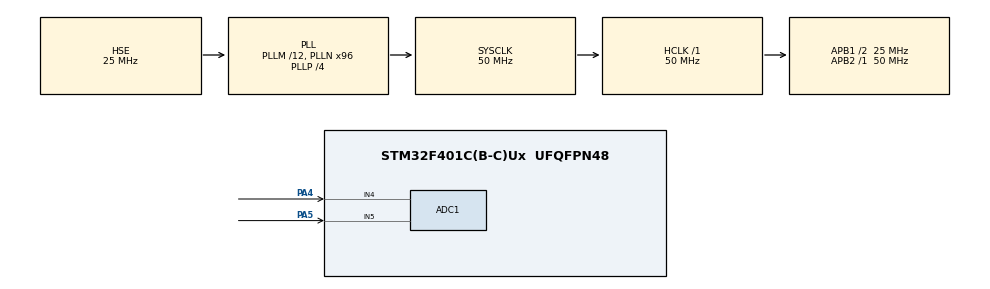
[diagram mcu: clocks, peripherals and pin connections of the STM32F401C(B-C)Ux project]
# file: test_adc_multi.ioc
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ADC1.Channel-0\#ChannelRegularConversion=ADC_CHANNEL_4
ADC1.Channel-1\#ChannelRegularConversion=ADC_CHANNEL_5
ADC1.ContinuousConvMode=ENABLE
ADC1.DMAContinuousRequests=ENABLE
ADC1.DiscontinuousConvMode=DISABLE
ADC1.EOCSelection=ADC_EOC_SEQ_CONV
ADC1.EnableAnalogWatchDog=false
ADC1.InjNumberOfConversion=0
ADC1.NbrOfConversion=2
ADC1.NbrOfConversionFlag=1
ADC1.Rank-0\#ChannelRegularConversion=1
ADC1.Rank-1\#ChannelRegularConversion=2
ADC1.SamplingTime-0\#ChannelRegularConversion=ADC_SAMPLETIME_480CYCLES
ADC1.SamplingTime-1\#ChannelRegularConversion=ADC_SAMPLETIME_480CYCLES
ADC1.ScanConvMode=ENABLE
ADC1.master=1
Dma.ADC1.0.Direction=DMA_PERIPH_TO_MEMORY
Dma.ADC1.0.FIFOMode=DMA_FIFOMODE_ENABLE
Dma.ADC1.0.FIFOThreshold=DMA_FIFO_THRESHOLD_FULL
Dma.ADC1.0.Instance=DMA2_Stream0
Dma.ADC1.0.MemBurst=DMA_MBURST_SINGLE
Dma.ADC1.0.MemDataAlignment=DMA_MDATAALIGN_HALFWORD
Dma.ADC1.0.MemInc=DMA_MINC_ENABLE
Dma.ADC1.0.Mode=DMA_CIRCULAR
Dma.ADC1.0.PeriphBurst=DMA_PBURST_SINGLE
Dma.ADC1.0.PeriphDataAlignment=DMA_PDATAALIGN_HALFWORD
Dma.ADC1.0.PeriphInc=DMA_PINC_DISABLE
Dma.ADC1.0.Priority=DMA_PRIORITY_LOW
Dma.Request0=ADC1
Mcu.Family=STM32F4
Mcu.Name=STM32F401C(B-C)Ux
Mcu.Package=UFQFPN48
NVIC.ADC_IRQn=true\:0\:0\:false\:false\:true\:true\:true\:true
NVIC.DMA2_Stream0_IRQn=true\:0\:0\:false\:false\:true\:false\:true\:true
NVIC.PriorityGroup=NVIC_PRIORITYGROUP_4
PA13.Mode=Serial_Wire
PA13.Signal=SYS_JTMS-SWDIO
PA14.Mode=Serial_Wire
PA14.Signal=SYS_JTCK-SWCLK
PA4.Signal=ADCx_IN4
PA5.Signal=ADCx_IN5
PH0\ -\ OSC_IN.Mode=HSE-External-Oscillator
PH0\ -\ OSC_IN.Signal=RCC_OSC_IN
PH1\ -\ OSC_OUT.Mode=HSE-External-Oscillator
PH1\ -\ OSC_OUT.Signal=RCC_OSC_OUT
ProjectManager.HeapSize=0x200
ProjectManager.StackSize=0x400
ProjectManager.TargetToolchain=MDK-ARM V5.32
RCC.48MHZClocksFreq_Value=50000000
RCC.AHBFreq_Value=50000000
RCC.APB1CLKDivider=RCC_HCLK_DIV2
RCC.APB1Freq_Value=25000000
RCC.APB1TimFreq_Value=50000000
RCC.APB2Freq_Value=50000000
RCC.APB2TimFreq_Value=50000000
RCC.CortexFreq_Value=50000000
RCC.HCLKFreq_Value=50000000
RCC.HSE_VALUE=25000000
RCC.HSI_VALUE=16000000
RCC.LSE_VALUE=32768
RCC.PLLM=12
RCC.PLLN=96
RCC.PLLP=RCC_PLLP_DIV4
RCC.PLLSourceVirtual=RCC_PLLSOURCE_HSE
RCC.SYSCLKFreq_VALUE=50000000
RCC.SYSCLKSource=RCC_SYSCLKSOURCE_PLLCLK
RCC.VCOOutputFreq_Value=200000000
SH.ADCx_IN4.0=ADC1_IN4,IN4
SH.ADCx_IN5.0=ADC1_IN5,IN5
board=custom

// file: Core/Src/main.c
/* USER CODE BEGIN Header */
/**
  ******************************************************************************
  * @file           : main.c
  * @brief          : Main program body
  ******************************************************************************
  * @attention
  *
  * Copyright (c) 2026 STMicroelectronics.
  * All rights reserved.
  *
  * This software is licensed under terms that can be found in the LICENSE file
  * in the root directory of this software component.
  * If no LICENSE file comes with this software, it is provided AS-IS.
  *
  ******************************************************************************
  */
/* USER CODE END Header */
#include "main.h"
#include "adc.h"
#include "dma.h"
#include "gpio.h"

/* USER CODE BEGIN PV */

uint16_t ADC_Value[2];
float Battery_Voltage[2];

/* USER CODE END PV */

void SystemClock_Config(void);

int main(void)
{

  /* MCU Configuration--------------------------------------------------------*/

  /* Reset of all peripherals, Initializes the Flash interface and the Systick. */
  HAL_Init();

  /* Configure the system clock */
  SystemClock_Config();

  /* Initialize all configured peripherals */
  MX_GPIO_Init();
  MX_DMA_Init();
  MX_ADC1_Init();
  /* USER CODE BEGIN 2 */

  HAL_ADC_Start_DMA(&hadc1, (uint32_t *)&ADC_Value, 2);

  /* USER CODE END 2 */

  /* Infinite loop */
  while (1)
  {

  }
}

void SystemClock_Config(void)
{
  RCC_OscInitTypeDef RCC_OscInitStruct = {0};
  RCC_ClkInitTypeDef RCC_ClkInitStruct = {0};

  /** Configure the main internal regulator output voltage
  */
  __HAL_RCC_PWR_CLK_ENABLE();
  __HAL_PWR_VOLTAGESCALING_CONFIG(PWR_REGULATOR_VOLTAGE_SCALE2);

  /** Initializes the RCC Oscillators according to the specified parameters
  * in the RCC_OscInitTypeDef structure.
  */
  RCC_OscInitStruct.OscillatorType = RCC_OSCILLATORTYPE_HSE;
  RCC_OscInitStruct.HSEState = RCC_HSE_ON;
  RCC_OscInitStruct.PLL.PLLState = RCC_PLL_ON;
  RCC_OscInitStruct.PLL.PLLSource = RCC_PLLSOURCE_HSE;
  RCC_OscInitStruct.PLL.PLLM = 12;
  RCC_OscInitStruct.PLL.PLLN = 96;
  RCC_OscInitStruct.PLL.PLLP = RCC_PLLP_DIV4;
  RCC_OscInitStruct.PLL.PLLQ = 4;
  if (HAL_RCC_OscConfig(&RCC_OscInitStruct) != HAL_OK)
  {
    Error_Handler();
  }

  /** Initializes the CPU, AHB and APB buses clocks
  */
  RCC_ClkInitStruct.ClockType = RCC_CLOCKTYPE_HCLK|RCC_CLOCKTYPE_SYSCLK
                              |RCC_CLOCKTYPE_PCLK1|RCC_CLOCKTYPE_PCLK2;
  RCC_ClkInitStruct.SYSCLKSource = RCC_SYSCLKSOURCE_PLLCLK;
  RCC_ClkInitStruct.AHBCLKDivider = RCC_SYSCLK_DIV1;
  RCC_ClkInitStruct.APB1CLKDivider = RCC_HCLK_DIV2;
  RCC_ClkInitStruct.APB2CLKDivider = RCC_HCLK_DIV1;

  if (HAL_RCC_ClockConfig(&RCC_ClkInitStruct, FLASH_LATENCY_1) != HAL_OK)
  {
    Error_Handler();
  }
}

/* USER CODE BEGIN 4 */

void HAL_ADC_ConvCpltCallback(ADC_HandleTypeDef* hadc)
{
  Battery_Voltage[0] = ADC_Value[0] / 4096.0f * 3.3f;
  Battery_Voltage[1] = ADC_Value[1] / 4096.0f * 3.3f;
}

/* USER CODE END 4 */

void Error_Handler(void)
{
  __disable_irq();
  while (1)
  {
  }
}
